# STM32F427x register map
File version: 1.1
Registers are 32-bit, read-write, reset 0x0 unless marked. A register's access mark holds for its fields unless they carry their own. Offsets are from the block's base; [hi:lo] are bit positions.

## DAC — Digital-to-analog converter
Base 0x40007400
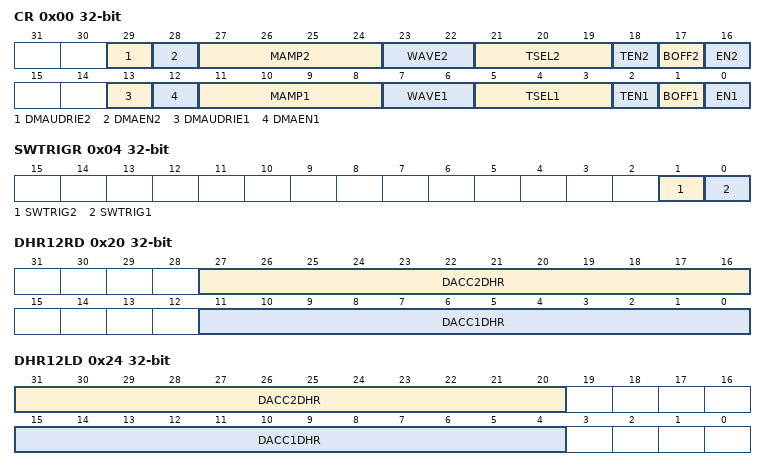
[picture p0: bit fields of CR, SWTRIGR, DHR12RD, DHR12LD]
0x00 CR — control register
  [29] DMAUDRIE2 — DAC channel2 DMA underrun interrupt enable
  [28] DMAEN2 — DAC channel2 DMA enable
  [27:24] MAMP2 — DAC channel2 mask/amplitude selector
  [23:22] WAVE2 — DAC channel2 noise/triangle wave generation enable
  [21:19] TSEL2 — DAC channel2 trigger selection
  [18] TEN2 — DAC channel2 trigger enable
  [17] BOFF2 — DAC channel2 output buffer disable
  [16] EN2 — DAC channel2 enable
  [13] DMAUDRIE1 — DAC channel1 DMA Underrun Interrupt enable
  [12] DMAEN1 — DAC channel1 DMA enable
  [11:8] MAMP1 — DAC channel1 mask/amplitude selector
  [7:6] WAVE1 — DAC channel1 noise/triangle wave generation enable
  [5:3] TSEL1 — DAC channel1 trigger selection
  [2] TEN1 — DAC channel1 trigger enable
  [1] BOFF1 — DAC channel1 output buffer disable
  [0] EN1 — DAC channel1 enable
0x04 SWTRIGR wo — software trigger register
  [1] SWTRIG2 — DAC channel2 software trigger
  [0] SWTRIG1 — DAC channel1 software trigger
0x08 DHR12R1 — channel1 12-bit right-aligned data holding register
  [11:0] DACC1DHR — DAC channel1 12-bit right-aligned data
0x0C DHR12L1 — channel1 12-bit left aligned data holding register
  [15:4] DACC1DHR — DAC channel1 12-bit left-aligned data
0x10 DHR8R1 — channel1 8-bit right aligned data holding register
  [7:0] DACC1DHR — DAC channel1 8-bit right-aligned data
0x14 DHR12R2 — channel2 12-bit right aligned data holding register
  [11:0] DACC2DHR — DAC channel2 12-bit right-aligned data
0x18 DHR12L2 — channel2 12-bit left aligned data holding register
  [15:4] DACC2DHR — DAC channel2 12-bit left-aligned data
0x1C DHR8R2 — channel2 8-bit right-aligned data holding register
  [7:0] DACC2DHR — DAC channel2 8-bit right-aligned data
0x20 DHR12RD — Dual DAC 12-bit right-aligned data holding register
  [27:16] DACC2DHR — DAC channel2 12-bit right-aligned data
  [11:0] DACC1DHR — DAC channel1 12-bit right-aligned data
0x24 DHR12LD — DUAL DAC 12-bit left aligned data holding register
  [31:20] DACC2DHR — DAC channel2 12-bit left-aligned data
  [15:4] DACC1DHR — DAC channel1 12-bit left-aligned data
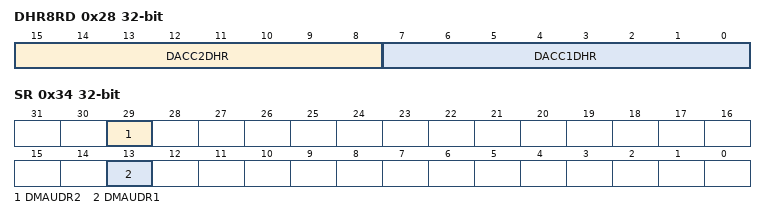
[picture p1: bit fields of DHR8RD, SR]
0x28 DHR8RD — DUAL DAC 8-bit right aligned data holding register
  [15:8] DACC2DHR — DAC channel2 8-bit right-aligned data
  [7:0] DACC1DHR — DAC channel1 8-bit right-aligned data
0x2C DOR1 ro — channel1 data output register
  [11:0] DACC1DOR — DAC channel1 data output
0x30 DOR2 ro — channel2 data output register
  [11:0] DACC2DOR — DAC channel2 data output
0x34 SR — status register
  [29] DMAUDR2 — DAC channel2 DMA underrun flag
  [13] DMAUDR1 — DAC channel1 DMA underrun flag

## PWR — Power control
Base 0x40007000
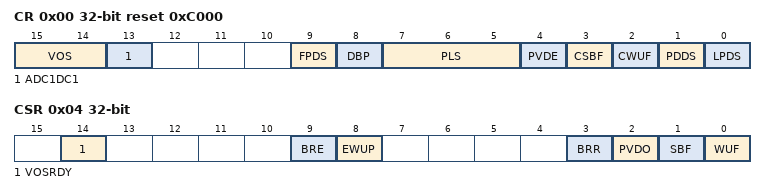
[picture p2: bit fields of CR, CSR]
0x00 CR reset 0xC000 — power control register
  [15:14] VOS — Regulator voltage scaling output selection
  [13] ADC1DC1
  [9] FPDS — Flash power down in Stop mode
  [8] DBP — Disable backup domain write protection
  [7:5] PLS — PVD level selection
  [4] PVDE — Power voltage detector enable
  [3] CSBF — Clear standby flag
  [2] CWUF — Clear wakeup flag
  [1] PDDS — Power down deepsleep
  [0] LPDS — Low-power deep sleep
0x04 CSR access per field — power control/status register
  [14] VOSRDY rw — Regulator voltage scaling output selection ready bit
  [9] BRE rw — Backup regulator enable
  [8] EWUP rw — Enable WKUP pin
  [3] BRR ro — Backup regulator ready
  [2] PVDO ro — PVD output
  [1] SBF ro — Standby flag
  [0] WUF ro — Wakeup flag

## I2C3 — Inter-integrated circuit
Base 0x40005C00
Same registers: I2C1 0x40005400, I2C2 0x40005800
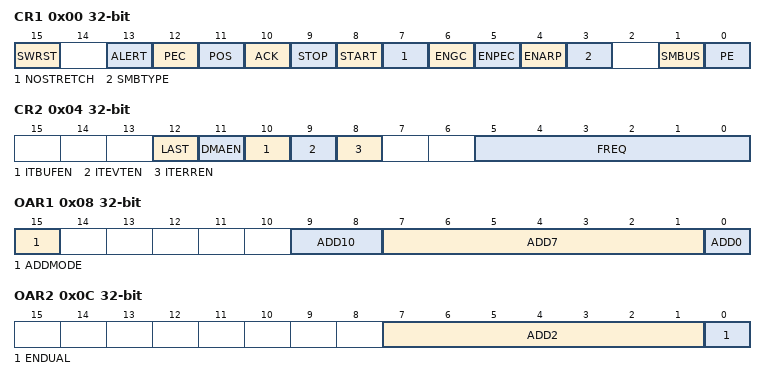
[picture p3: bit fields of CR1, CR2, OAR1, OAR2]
0x00 CR1 — Control register 1
  [15] SWRST — Software reset
  [13] ALERT — SMBus alert
  [12] PEC — Packet error checking
  [11] POS — Acknowledge/PEC Position (for data reception)
  [10] ACK — Acknowledge enable
  [9] STOP — Stop generation
  [8] START — Start generation
  [7] NOSTRETCH — Clock stretching disable (Slave mode)
  [6] ENGC — General call enable
  [5] ENPEC — PEC enable
  [4] ENARP — ARP enable
  [3] SMBTYPE — SMBus type
  [1] SMBUS — SMBus mode
  [0] PE — Peripheral enable
0x04 CR2 — Control register 2
  [12] LAST — DMA last transfer
  [11] DMAEN — DMA requests enable
  [10] ITBUFEN — Buffer interrupt enable
  [9] ITEVTEN — Event interrupt enable
  [8] ITERREN — Error interrupt enable
  [5:0] FREQ — Peripheral clock frequency
0x08 OAR1 — Own address register 1
  [15] ADDMODE — Addressing mode (slave mode)
  [9:8] ADD10 — Interface address
  [7:1] ADD7 — Interface address
  [0] ADD0 — Interface address
0x0C OAR2 — Own address register 2
  [7:1] ADD2 — Interface address
  [0] ENDUAL — Dual addressing mode enable
0x10 DR — Data register
  [7:0] DR — 8-bit data register
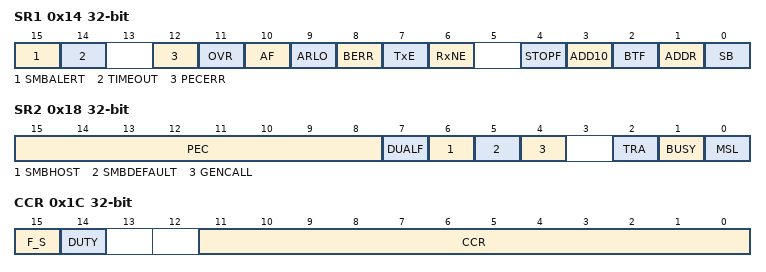
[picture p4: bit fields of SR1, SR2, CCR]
0x14 SR1 access per field — Status register 1
  [15] SMBALERT rw — SMBus alert
  [14] TIMEOUT rw — Timeout or Tlow error
  [12] PECERR rw — PEC Error in reception
  [11] OVR rw — Overrun/Underrun
  [10] AF rw — Acknowledge failure
  [9] ARLO rw — Arbitration lost (master mode)
  [8] BERR rw — Bus error
  [7] TxE ro — Data register empty (transmitters)
  [6] RxNE ro — Data register not empty (receivers)
  [4] STOPF ro — Stop detection (slave mode)
  [3] ADD10 ro — 10-bit header sent (Master mode)
  [2] BTF ro — Byte transfer finished
  [1] ADDR ro — Address sent (master mode)/matched (slave mode)
  [0] SB ro — Start bit (Master mode)
0x18 SR2 ro — Status register 2
  [15:8] PEC — acket error checking register
  [7] DUALF — Dual flag (Slave mode)
  [6] SMBHOST — SMBus host header (Slave mode)
  [5] SMBDEFAULT — SMBus device default address (Slave mode)
  [4] GENCALL — General call address (Slave mode)
  [2] TRA — Transmitter/receiver
  [1] BUSY — Bus busy
  [0] MSL — Master/slave
0x1C CCR — Clock control register
  [15] F_S — I2C master mode selection
  [14] DUTY — Fast mode duty cycle
  [11:0] CCR — Clock control register in Fast/Standard mode (Master mode)
0x20 TRISE reset 0x2
  [5:0] TRISE — Maximum rise time in Fast/Standard mode (Master mode)
